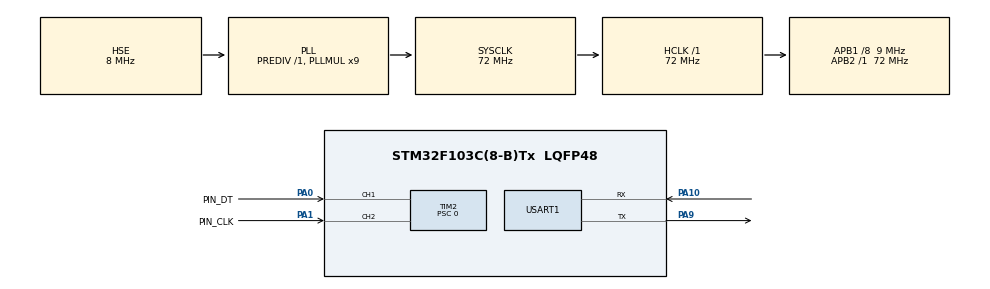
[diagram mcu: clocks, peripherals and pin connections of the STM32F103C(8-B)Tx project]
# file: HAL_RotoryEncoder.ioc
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Mcu.Family=STM32F1
Mcu.Name=STM32F103C(8-B)Tx
Mcu.Package=LQFP48
NVIC.PriorityGroup=NVIC_PRIORITYGROUP_4
PA0-WKUP.GPIO_Label=PIN_DT
PA0-WKUP.Signal=S_TIM2_CH1_ETR
PA1.GPIO_Label=PIN_CLK
PA1.Signal=S_TIM2_CH2
PA10.Mode=Asynchronous
PA10.Signal=USART1_RX
PA9.Mode=Asynchronous
PA9.Signal=USART1_TX
PD0-OSC_IN.Mode=HSE-External-Oscillator
PD0-OSC_IN.Signal=RCC_OSC_IN
PD1-OSC_OUT.Mode=HSE-External-Oscillator
PD1-OSC_OUT.Signal=RCC_OSC_OUT
ProjectManager.HeapSize=0x200
ProjectManager.StackSize=0x400
ProjectManager.TargetToolchain=STM32CubeIDE
RCC.AHBFreq_Value=72000000
RCC.APB1CLKDivider=RCC_HCLK_DIV8
RCC.APB1Freq_Value=9000000
RCC.APB1TimFreq_Value=18000000
RCC.APB2Freq_Value=72000000
RCC.APB2TimFreq_Value=72000000
RCC.HCLKFreq_Value=72000000
RCC.PLLMUL=RCC_PLL_MUL9
RCC.PLLSourceVirtual=RCC_PLLSOURCE_HSE
RCC.SYSCLKFreq_VALUE=72000000
RCC.SYSCLKSource=RCC_SYSCLKSOURCE_PLLCLK
RCC.USBFreq_Value=72000000
SH.S_TIM2_CH1_ETR.0=TIM2_CH1,Encoder_Interface
SH.S_TIM2_CH2.0=TIM2_CH2,Encoder_Interface
TIM2.AutoReloadPreload=TIM_AUTORELOAD_PRELOAD_ENABLE
TIM2.EncoderMode=TIM_ENCODERMODE_TI12
TIM2.IC1Filter=10
TIM2.IC2Filter=10
TIM2.Period=65534
TIM2.Prescaler=0
USART1.VirtualMode=VM_ASYNC
board=custom

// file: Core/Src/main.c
/* USER CODE BEGIN Header */
/**
  ******************************************************************************
  * @file           : main.c
  * @brief          : Main program body
  ******************************************************************************
  * @attention
  *
  * Copyright (c) 2023 STMicroelectronics.
  * All rights reserved.
  *
  * This software is licensed under terms that can be found in the LICENSE file
  * in the root directory of this software component.
  * If no LICENSE file comes with this software, it is provided AS-IS.
  *
  ******************************************************************************
  */
/* USER CODE END Header */
#include "main.h"

/* USER CODE BEGIN PD */

/* Pin mapping

PA0 -> DT
PA1 -> CLK

*/

/* USER CODE END PD */

TIM_HandleTypeDef htim2;

UART_HandleTypeDef huart1;

/* USER CODE BEGIN PV */
uint8_t transmit_buffer[100];
uint32_t count = 0;

uint32_t clkvalue =0, dtvalue = 0;
/* USER CODE END PV */

void SystemClock_Config(void);
static void MX_GPIO_Init(void);
static void MX_USART1_UART_Init(void);
static void MX_TIM2_Init(void);

int main(void)
{
  /* USER CODE BEGIN 1 */
	int length;
  /* USER CODE END 1 */

  /* MCU Configuration--------------------------------------------------------*/

  /* Reset of all peripherals, Initializes the Flash interface and the Systick. */
  HAL_Init();

  /* Configure the system clock */
  SystemClock_Config();

  /* Initialize all configured peripherals */
  MX_GPIO_Init();
  MX_USART1_UART_Init();
  MX_TIM2_Init();
  /* USER CODE BEGIN 2 */
  HAL_TIM_Encoder_Start(&htim2, TIM_CHANNEL_ALL);
  /* USER CODE END 2 */

  /* Infinite loop */
  while (1)
  {

    /* USER CODE BEGIN 3 */
	  /*
	clkvalue = HAL_GPIO_ReadPin(PIN_CLK_GPIO_Port, PIN_CLK_Pin);
	dtvalue = HAL_GPIO_ReadPin(PIN_DT_GPIO_Port, PIN_DT_Pin);

	memset(transmit_buffer, 0, 100);
	length = snprintf(transmit_buffer, 100, "CLk Value - %d Dt value - %d", clkvalue, dtvalue);
	transmit_buffer[length++] = '\n';
	transmit_buffer[length++] = '\r';

	HAL_UART_Transmit(&huart1, transmit_buffer, length, HAL_MAX_DELAY);
	*/

	memset(transmit_buffer, 0, 100);
	length = snprintf(transmit_buffer, 100, "tick Value %d\n\r", ((TIM2->CNT)));
	HAL_UART_Transmit(&huart1, transmit_buffer, length, HAL_MAX_DELAY);

	HAL_Delay(1000);
  }
  /* USER CODE END 3 */
}

void SystemClock_Config(void)
{
  RCC_OscInitTypeDef RCC_OscInitStruct = {0};
  RCC_ClkInitTypeDef RCC_ClkInitStruct = {0};

  /** Initializes the RCC Oscillators according to the specified parameters
  * in the RCC_OscInitTypeDef structure.
  */
  RCC_OscInitStruct.OscillatorType = RCC_OSCILLATORTYPE_HSE;
  RCC_OscInitStruct.HSEState = RCC_HSE_ON;
  RCC_OscInitStruct.HSEPredivValue = RCC_HSE_PREDIV_DIV1;
  RCC_OscInitStruct.HSIState = RCC_HSI_ON;
  RCC_OscInitStruct.PLL.PLLState = RCC_PLL_ON;
  RCC_OscInitStruct.PLL.PLLSource = RCC_PLLSOURCE_HSE;
  RCC_OscInitStruct.PLL.PLLMUL = RCC_PLL_MUL9;
  if (HAL_RCC_OscConfig(&RCC_OscInitStruct) != HAL_OK)
  {
    Error_Handler();
  }

  /** Initializes the CPU, AHB and APB buses clocks
  */
  RCC_ClkInitStruct.ClockType = RCC_CLOCKTYPE_HCLK|RCC_CLOCKTYPE_SYSCLK
                              |RCC_CLOCKTYPE_PCLK1|RCC_CLOCKTYPE_PCLK2;
  RCC_ClkInitStruct.SYSCLKSource = RCC_SYSCLKSOURCE_PLLCLK;
  RCC_ClkInitStruct.AHBCLKDivider = RCC_SYSCLK_DIV1;
  RCC_ClkInitStruct.APB1CLKDivider = RCC_HCLK_DIV8;
  RCC_ClkInitStruct.APB2CLKDivider = RCC_HCLK_DIV1;

  if (HAL_RCC_ClockConfig(&RCC_ClkInitStruct, FLASH_LATENCY_2) != HAL_OK)
  {
    Error_Handler();
  }
}

static void MX_TIM2_Init(void)
{

  TIM_Encoder_InitTypeDef sConfig = {0};
  TIM_MasterConfigTypeDef sMasterConfig = {0};

  htim2.Instance = TIM2;
  htim2.Init.Prescaler = 0;
  htim2.Init.CounterMode = TIM_COUNTERMODE_UP;
  htim2.Init.Period = 65534;
  htim2.Init.ClockDivision = TIM_CLOCKDIVISION_DIV1;
  htim2.Init.AutoReloadPreload = TIM_AUTORELOAD_PRELOAD_ENABLE;
  sConfig.EncoderMode = TIM_ENCODERMODE_TI12;
  sConfig.IC1Polarity = TIM_ICPOLARITY_RISING;
  sConfig.IC1Selection = TIM_ICSELECTION_DIRECTTI;
  sConfig.IC1Prescaler = TIM_ICPSC_DIV1;
  sConfig.IC1Filter = 10;
  sConfig.IC2Polarity = TIM_ICPOLARITY_RISING;
  sConfig.IC2Selection = TIM_ICSELECTION_DIRECTTI;
  sConfig.IC2Prescaler = TIM_ICPSC_DIV1;
  sConfig.IC2Filter = 10;
  if (HAL_TIM_Encoder_Init(&htim2, &sConfig) != HAL_OK)
  {
    Error_Handler();
  }
  sMasterConfig.MasterOutputTrigger = TIM_TRGO_RESET;
  sMasterConfig.MasterSlaveMode = TIM_MASTERSLAVEMODE_DISABLE;
  if (HAL_TIMEx_MasterConfigSynchronization(&htim2, &sMasterConfig) != HAL_OK)
  {
    Error_Handler();
  }

}

static void MX_USART1_UART_Init(void)
{

  huart1.Instance = USART1;
  huart1.Init.BaudRate = 115200;
  huart1.Init.WordLength = UART_WORDLENGTH_8B;
  huart1.Init.StopBits = UART_STOPBITS_1;
  huart1.Init.Parity = UART_PARITY_NONE;
  huart1.Init.Mode = UART_MODE_TX_RX;
  huart1.Init.HwFlowCtl = UART_HWCONTROL_NONE;
  huart1.Init.OverSampling = UART_OVERSAMPLING_16;
  if (HAL_UART_Init(&huart1) != HAL_OK)
  {
    Error_Handler();
  }

}

static void MX_GPIO_Init(void)
{

  /* GPIO Ports Clock Enable */
  __HAL_RCC_GPIOD_CLK_ENABLE();
  __HAL_RCC_GPIOA_CLK_ENABLE();

}

void Error_Handler(void)
{
  __disable_irq();
  while (1)
  {
  }
}
